# K32W041AM register map
Vendor: nxp.com; File version: 1.0
CPU: CM4 r0p1, little endian, MPU, no FPU, VTOR, 3 interrupt priority bits
Registers are 32-bit, read-write, reset 0x0 unless marked. A register's access mark holds for its fields unless they carry their own. Offsets are from the block's base; [hi:lo] are bit positions; lines under a group give offsets from that group; {n}, {i} and the like mark numbered series.

## INPUTMUX — This is the description of component input mux. . More details will follow.
Base 0x4000E000
{0xC0+4i} PINTSEL[{i}] (i=0..7) reset 0x1F — Pin interrupt select register
  [4:0] INTPIN — Pin number select for pin interrupt or pattern match engine input.
{0xE0+4i} DMA_ITRIG_INMUX[{i}] (i=0..18) reset 0x1F — Trigger select register for DMA channel. Configurable for each of the DMA channels.
  [4:0] INP — Trigger input number (decimal value) for DMA channel n (n = 0 to 17). 0: ADC0 Sequence A interrupt; 1: Reserved; 2: Timer CT32B0 Match 0; 3: Timer CT32B0 Match 1; 4: Timer CT32B1 Match 0; 5: Timer CT32B1 Match 1; 6: Pin interrupt 0; 7: Pin interrupt 1; 8: Pin interrupt 2; 9: Pin interrupt 3; 10: AES RX; 11: AES TX; 12: Hash RX; 13: Hash TX; 14: DMA output trigger mux 0; 15: DMA output trigger mux 1; 16: DMA output trigger mux 2; 17: DMA output trigger mux 3; 18- 31: reserved.
{0x160+4i} DMA_OTRIG_INMUX[{i}] (i=0..3) reset 0x1F — DMA output trigger selection to become an input to the DMA trigger mux. Four selections can be made.
  [4:0] INP — DMA trigger output number (decimal value) for DMA channel n (n = 0 to 19).
0x180 FREQMEAS_REF reset 0xF — Selection for frequency measurement reference clock
  [3:0] CLKIN — Clock source number (decimal value) for frequency measure function ref clock: 0: CLK_IN (must be enabled in functional mux); 1: XTAL 32 MHz (must be enabled in clock_ctrl); 2: FRO 1 MHz (must be enabled in clock_ctrl); 3: 32 kHz oscillator (either FRO 32 KHz or XTAL 32 KHZ); 4: Main clock (divided); 5: PIO[4] (must be configured as GPIO); 6: PIO[20] (must be configured as GPIO); 7: PIO[16] (must be configured as GPIO); 8: PIO[15] (must be configured as GPIO); 9 - 15: reserved.
0x184 FREQMEAS_TARGET reset 0xF — Selection for frequency measurement target clock
  [3:0] CLKIN — Clock source number (decimal value) for frequency measure function target clock: 0: CLK_IN (must be enabled in functional mux); 1: XTAL 32 MHz (must be enabled in clock_ctrl); 2: FRO 1 MHz (must be enabled in clock_ctrl); 3: 32 kHz oscillator (either FRO 32 KHz or XTAL 32 KHZ); 4: Main clock (divided); 5: PIO[4] (must be configured as GPIO); 6: PIO[20] (must be configured as GPIO); 7: PIO[16] (must be configured as GPIO); 8: PIO[15] (must be configured as GPIO); 9 - 15: reserved.

## GINT0 — This is the description of component gint It is an Global Interrupt with APB bus interface. More details will follow.
Base 0x40011000
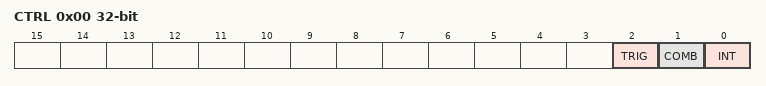
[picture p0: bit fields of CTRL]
0x00 CTRL — GPIO Grouped interrupt control register
  [2] TRIG — Group interrupt trigger. 0: Edge Triggered. 1: Level Triggered.
  [1] COMB — Combine enabled inputs for group interrupt. 0: Or, OR functionality: A grouped interrupt is generated when any one of the enabled inputs is active (based on its programmed polarity) 1: And, AND functionality: An interrupt is generated when all enabled bits are active (based on their programmed polarity)
  [0] INT — Group interrupt status. This bit is cleared by writing a one to it. Writing zero has no effect.
0x20 PORT_POL0 reset 0xFFFFFFFF — GPIO Grouped Interrupt polarity register. Configure the pin polarity of each PIO signal into the group interrupt function. If a bit is low then the corresponding PIO has an active low contribution into the group interrupt. If a bit is high then the corresponding PIO has an active high contribution.
  [21:0] POL — Configure pin polarity of pin PIOn.
0x40 PORT_ENA0 — GPIO Grouped Interrupt port enable register. When a bit is set then the corresponding PIO is enabled for the group interrupt function.
  [21:0] ENA — Enable pin PIOn for group interrupt.

## BLE_DP_TOP — This is the description of component ble_dp_top. It is Bluetooth Low Energy Data Path module APB bus interface. More details will follow.
Base 0x40014000
0xB0 ANT_DIVERSITY — Antenna diversity
  [0] ble_ant_selected — Selection of antenna when selection mode is direct from register, see ble_ant_mode. 0: ADE is asserted. 1: ADE de-asserted. ADO is always the inverse of ADE and so is also controlled by this setting as well.
